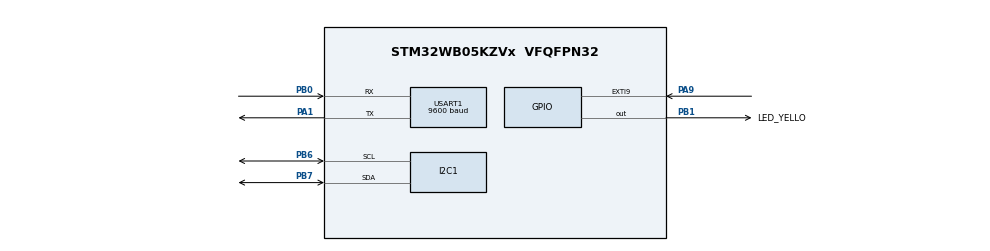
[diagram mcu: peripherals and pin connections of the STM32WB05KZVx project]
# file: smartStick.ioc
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I2C1.Timing=0x00303D5B
Mcu.Family=STM32WB0
Mcu.Name=STM32WB05KZVx
Mcu.Package=VFQFPN32
NVIC.GPIOA_IRQn=true\:1\:0\:false\:false\:true\:true\:true\:true
NVIC.I2C1_IRQn=true\:1\:0\:false\:false\:true\:true\:true\:true
NVIC.RADIO_RRM_IRQn=true\:0\:0\:false\:false\:true\:false\:true\:true
NVIC.RADIO_TIMER_CPU_WKUP_IRQn=true\:0\:0\:false\:false\:true\:false\:true\:true
NVIC.RADIO_TIMER_ERROR_IRQn=true\:0\:0\:false\:false\:true\:false\:true\:true
NVIC.RADIO_TXRX_IRQn=true\:0\:0\:false\:false\:true\:false\:true\:true
NVIC.RADIO_TXRX_SEQ_IRQn=true\:0\:0\:false\:false\:true\:false\:true\:true
NVIC.TIM16_IRQn=true\:1\:0\:false\:false\:true\:true\:true\:true
NVIC.USART1_IRQn=true\:1\:0\:false\:false\:true\:true\:true\:true
OSCIN.Mode=HSE-External-Oscillator
OSCIN.Signal=RCC_OSC_IN
OSCOUT.Mode=HSE-External-Oscillator
OSCOUT.Signal=RCC_OSC_OUT
PA1.Mode=Asynchronous
PA1.Signal=USART1_TX
PA9.GPIO_PuPd=GPIO_PULLDOWN
PA9.Signal=GPXTI9
PB0.Mode=Asynchronous
PB0.Signal=USART1_RX
PB1.GPIO_Label=LED_YELLO
PB1.Signal=GPIO_Output
PB12.Mode=LSE-External-Oscillator
PB12.Signal=RCC_OSC32_OUT
PB13.Mode=LSE-External-Oscillator
PB13.Signal=RCC_OSC32_IN
PB6.Mode=I2C
PB6.Signal=I2C1_SCL
PB7.Mode=I2C
PB7.Signal=I2C1_SDA
ProjectManager.HeapSize=0x000
ProjectManager.StackSize=0xC00
ProjectManager.TargetToolchain=STM32CubeIDE
RCC.BLEMultSource=RCC_RF_CLK_16M
RCC.HSE_VALUE=32000000
RCC.HSI_VALUE=64000000
RCC.RC64MPLLSource=RCC_LSCOSOURCE_PLL64
RCC.RTCClockSelection=RCC_RTC_WDG_BLEWKUP_CLKSOURCE_LSE
RF1.Mode=RF1_Activate
RF1.Signal=RADIO_RF1
STM32_BLE.AD_TYPE_COMPLETE_LOCAL_NAME=WMU_Heat30
STM32_BLE.AD_TYPE_COMPLETE_LOCAL_NAME_LENGTH=11
STM32_BLE.AD_TYPE_MANUFACTURER_DATA_NBR=12
STM32_BLE.BSP.number=1
STM32_BLE.CFG_GAP_DEVICE_NAME=WMU_Heat30
STM32_BLE.CFG_GAP_DEVICE_NAME_LENGTH=10
STM32_BLE.COMMON_BLE_STATUS-BLE_Server=Disabled
STM32_BLE.INCLUDE_AD_TYPE_COMPLETE_LOCAL_NAME=1
STM32_BLE.INCLUDE_AD_TYPE_MANUFACTURER_SPECIFIC_DATA=1
STM32_BLE.NUMBER_OF_SERVICES=1
STM32_BLE.SERVICE1_CHAR1_GATT_NOTIFY_READ_REQ_AND_WAIT_FOR_APPL_RESP=\ 
STM32_BLE.SERVICE1_CHAR1_GATT_NOTIFY_WRITE_REQ_AND_WAIT_FOR_APPL_RESP=\ 
STM32_BLE.SERVICE1_CHAR1_LENGTH_CHARACTERISTIC=CHAR_VALUE_LEN_VARIABLE
STM32_BLE.SERVICE1_CHAR1_LONG_NAME=My_PWM_Char
STM32_BLE.SERVICE1_CHAR1_PROP_READ=BLE_GATT_SRV_CHAR_PROP_READ
STM32_BLE.SERVICE1_CHAR1_PROP_WRITE_NO_RESP=BLE_GATT_SRV_CHAR_PROP_WRITE_NO_RESP
STM32_BLE.SERVICE1_CHAR1_SHORT_NAME=PWM_C
STM32_BLE.SERVICE1_CHAR1_UUID=19 ED 82 AE ED 21 4C 9D 41 45 22 8E 41 FE 00 00
STM32_BLE.SERVICE1_CHAR1_UUID_128_INPUT_TYPE=1
STM32_BLE.SERVICE1_CHAR1_VALUE_LENGTH=2
STM32_BLE.SERVICE1_CHAR2_GATT_NOTIFY_READ_REQ_AND_WAIT_FOR_APPL_RESP=\ 
STM32_BLE.SERVICE1_CHAR2_GATT_NOTIFY_WRITE_REQ_AND_WAIT_FOR_APPL_RESP=\ 
STM32_BLE.SERVICE1_CHAR2_LENGTH_CHARACTERISTIC=CHAR_VALUE_LEN_VARIABLE
STM32_BLE.SERVICE1_CHAR2_LONG_NAME=My_Temp_Char
STM32_BLE.SERVICE1_CHAR2_PROP_NOTIFY=BLE_GATT_SRV_CHAR_PROP_NOTIFY
STM32_BLE.SERVICE1_CHAR2_SHORT_NAME=TEMP_C
STM32_BLE.SERVICE1_CHAR2_UUID=A8 26 1B 36 07 EA F5 B7 88 46 E1 36 3E 48 B5 BE
STM32_BLE.SERVICE1_CHAR2_UUID_128_INPUT_TYPE=1
STM32_BLE.SERVICE1_CHAR2_VALUE_LENGTH=4
STM32_BLE.SERVICE1_LONG_NAME=P2P_Server
STM32_BLE.SERVICE1_NUMBER_OF_CHARACTERISTICS=2
STM32_BLE.SERVICE1_SHORT_NAME=P2P_Server
STM32_BLE.SERVICE1_UUID=4B 91 31 C3 C9 C5 CC 8F 9E 45 B5 1F 01 C2 AF 4F
STM32_BLE.SERVICE1_UUID_128_INPUT_TYPE=1
STM32_BLE0.BSP.STBoard=false
STM32_BLE0.BSP.api=Unknown
STM32_BLE0.BSP.instance=USART1
STM32_BLE0.BSP.ip=(LPU|US)ART
STM32_BLE0.BSP.mode=Asynchronous
STM32_BLE0.BSP.name=Serial Link for Traces
STM32_BLE0.BSP.solution=USART1
TIM16.Period=50000-1
TIM16.Prescaler=6400-1
USART1.BaudRate=9600
USART1.VirtualMode-Asynchronous=VM_ASYNC
VP_ADV_TRACE_VS_ADV_TRACE.Mode=ADV_TRACE_Enabled
VP_MEMORYMAP_VS_MEMORYMAP.Mode=CurAppReg
VP_MISC_VS_MISC.Mode=MISC_Enabled
VP_PKA_VS_PKA.Mode=PKA_Activate
VP_PWR_VS_SECSignals.Mode=Security/Privilege
VP_RADIO_TIMER_VS_RADIO.Mode=RADIO_Activate
VP_RNG_VS_RNG.Mode=RNG_Activate
VP_SEQUENCER_VS_SEQUENCER.Mode=SEQUENCER_Enabled
VP_STM32_BLE_VS_BLE_HOST_SP.Mode=BLE_Server
VP_TIM16_VS_ClockSourceINT.Mode=Enable_Timer
VP_TINY_LPM_VS_TINY_LPM.Mode=TINY_LPM_Enabled
board=custom

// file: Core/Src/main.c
/* USER CODE BEGIN Header */
/**
  ******************************************************************************
  * @file           : main.c
  * @brief          : Main program body
  ******************************************************************************
  * @attention
  *
  * Copyright (c) 2025 STMicroelectronics.
  * All rights reserved.
  *
  * This software is licensed under terms that can be found in the LICENSE file
  * in the root directory of this software component.
  * If no LICENSE file comes with this software, it is provided AS-IS.
  *
  ******************************************************************************
  */
/* USER CODE END Header */
#include "main.h"

/* USER CODE BEGIN Includes */
#include <stdio.h>
#include <string.h>

#include "air_app.h"
#include "bma456_app.h"
/* USER CODE END Includes */

I2C_HandleTypeDef hi2c1;

PKA_HandleTypeDef hpka;

RNG_HandleTypeDef hrng;

TIM_HandleTypeDef htim16;

UART_HandleTypeDef huart1;

void SystemClock_Config(void);
void PeriphCommonClock_Config(void);
static void MX_GPIO_Init(void);
static void MX_I2C1_Init(void);
static void MX_RNG_Init(void);
static void MX_RADIO_Init(void);
static void MX_RADIO_TIMER_Init(void);
static void MX_PKA_Init(void);
static void MX_TIM16_Init(void);
/* USER CODE BEGIN PFP */
void MX_USART1_UART_Init(void);
/* USER CODE END PFP */

int main(void)
{

  /* MCU Configuration--------------------------------------------------------*/

  /* Reset of all peripherals, Initializes the Flash interface and the Systick. */
  HAL_Init();

  /* Configure the system clock */
  SystemClock_Config();

  /* Configure the peripherals common clocks */
  PeriphCommonClock_Config();

  /* Initialize all configured peripherals */
  MX_GPIO_Init();
  MX_I2C1_Init();
  MX_RNG_Init();
  MX_RADIO_Init();
  MX_RADIO_TIMER_Init();
  MX_PKA_Init();
  MX_TIM16_Init();
  /* USER CODE BEGIN 2 */
  MX_USART1_UART_Init();

  if (air_app_init(&hi2c1, &huart1) != HAL_OK)
    {
      /* simple fault indication */
      HAL_Delay(200);
    }

  /* Initialize BMA456 accelerometer for impact detection */
  HAL_StatusTypeDef bma_status = bma456_app_init(&hi2c1, &huart1);
  if (bma_status != HAL_OK)
    {
      /* BMA456 initialization failed - continue anyway */
      HAL_Delay(100);
    }

  /* USER CODE END 2 */

  /* Init code for STM32_BLE */
  //MX_APPE_Init(NULL);

  /* Infinite loop */
  while (1)
  {
    //MX_APPE_Process();

    /* USER CODE BEGIN 3 */
	  air_app_process();
	      HAL_Delay(10); // small idle delay; BSEC scheduling still works
  }
  /* USER CODE END 3 */
}

void SystemClock_Config(void)
{
  RCC_OscInitTypeDef RCC_OscInitStruct = {0};
  RCC_ClkInitTypeDef RCC_ClkInitStruct = {0};

  /** Initializes the RCC Oscillators according to the specified parameters
  * in the RCC_OscInitTypeDef structure.
  */
  RCC_OscInitStruct.OscillatorType = RCC_OSCILLATORTYPE_HSE|RCC_OSCILLATORTYPE_LSE;
  RCC_OscInitStruct.HSEState = RCC_HSE_ON;
  RCC_OscInitStruct.LSEState = RCC_LSE_ON;
  if (HAL_RCC_OscConfig(&RCC_OscInitStruct) != HAL_OK)
  {
    Error_Handler();
  }

  /** Configure the SYSCLKSource and SYSCLKDivider
  */
  RCC_ClkInitStruct.SYSCLKSource = RCC_SYSCLKSOURCE_RC64MPLL;
  RCC_ClkInitStruct.SYSCLKDivider = RCC_RC64MPLL_DIV1;

  if (HAL_RCC_ClockConfig(&RCC_ClkInitStruct, FLASH_WAIT_STATES_1) != HAL_OK)
  {
    Error_Handler();
  }
}

void PeriphCommonClock_Config(void)
{
  RCC_PeriphCLKInitTypeDef PeriphClkInitStruct = {0};

  /** Initializes the peripherals clock
  */
  PeriphClkInitStruct.PeriphClockSelection = RCC_PERIPHCLK_SMPS;
  PeriphClkInitStruct.SmpsDivSelection = RCC_SMPSCLK_DIV4;

  if (HAL_RCCEx_PeriphCLKConfig(&PeriphClkInitStruct) != HAL_OK)
  {
    Error_Handler();
  }
}

static void MX_I2C1_Init(void)
{

  hi2c1.Instance = I2C1;
  hi2c1.Init.Timing = 0x00303D5B;
  hi2c1.Init.OwnAddress1 = 0;
  hi2c1.Init.AddressingMode = I2C_ADDRESSINGMODE_7BIT;
  hi2c1.Init.DualAddressMode = I2C_DUALADDRESS_DISABLE;
  hi2c1.Init.OwnAddress2 = 0;
  hi2c1.Init.OwnAddress2Masks = I2C_OA2_NOMASK;
  hi2c1.Init.GeneralCallMode = I2C_GENERALCALL_DISABLE;
  hi2c1.Init.NoStretchMode = I2C_NOSTRETCH_DISABLE;
  if (HAL_I2C_Init(&hi2c1) != HAL_OK)
  {
    Error_Handler();
  }

  /** Configure Analogue filter
  */
  if (HAL_I2CEx_ConfigAnalogFilter(&hi2c1, I2C_ANALOGFILTER_ENABLE) != HAL_OK)
  {
    Error_Handler();
  }

  /** Configure Digital filter
  */
  if (HAL_I2CEx_ConfigDigitalFilter(&hi2c1, 0) != HAL_OK)
  {
    Error_Handler();
  }

}

static void MX_PKA_Init(void)
{

  hpka.Instance = PKA;
  if (HAL_PKA_Init(&hpka) != HAL_OK)
  {
    Error_Handler();
  }

}

static void MX_RADIO_Init(void)
{

  RADIO_HandleTypeDef hradio = {0};

  if (__HAL_RCC_RADIO_IS_CLK_DISABLED())
  {
    /* Radio Peripheral reset */
    __HAL_RCC_RADIO_FORCE_RESET();
    __HAL_RCC_RADIO_RELEASE_RESET();

    /* Enable Radio peripheral clock */
    __HAL_RCC_RADIO_CLK_ENABLE();
  }
  hradio.Instance = RADIO;
  HAL_RADIO_Init(&hradio);

}

static void MX_RADIO_TIMER_Init(void)
{

  RADIO_TIMER_InitTypeDef RADIO_TIMER_InitStruct = {0};

  if (__HAL_RCC_RADIO_IS_CLK_DISABLED())
  {
    /* Radio Peripheral reset */
    __HAL_RCC_RADIO_FORCE_RESET();
    __HAL_RCC_RADIO_RELEASE_RESET();

    /* Enable Radio peripheral clock */
    __HAL_RCC_RADIO_CLK_ENABLE();
  }
  /* Wait to be sure that the Radio Timer is active */
  while(LL_RADIO_TIMER_GetAbsoluteTime(WAKEUP) < 0x10);
  RADIO_TIMER_InitStruct.XTAL_StartupTime = 320;
  RADIO_TIMER_InitStruct.enableInitialCalibration = FALSE;
  RADIO_TIMER_InitStruct.periodicCalibrationInterval = 0;
  HAL_RADIO_TIMER_Init(&RADIO_TIMER_InitStruct);

}

static void MX_RNG_Init(void)
{

  hrng.Instance = RNG;
  if (HAL_RNG_Init(&hrng) != HAL_OK)
  {
    Error_Handler();
  }

}

static void MX_TIM16_Init(void)
{

  htim16.Instance = TIM16;
  htim16.Init.Prescaler = 6400-1;
  htim16.Init.CounterMode = TIM_COUNTERMODE_UP;
  htim16.Init.Period = 50000-1;
  htim16.Init.ClockDivision = TIM_CLOCKDIVISION_DIV1;
  htim16.Init.RepetitionCounter = 0;
  htim16.Init.AutoReloadPreload = TIM_AUTORELOAD_PRELOAD_DISABLE;
  if (HAL_TIM_Base_Init(&htim16) != HAL_OK)
  {
    Error_Handler();
  }

}

void MX_USART1_UART_Init(void)
{

  huart1.Instance = USART1;
  huart1.Init.BaudRate = 9600;
  huart1.Init.WordLength = UART_WORDLENGTH_8B;
  huart1.Init.StopBits = UART_STOPBITS_1;
  huart1.Init.Parity = UART_PARITY_NONE;
  huart1.Init.Mode = UART_MODE_TX_RX;
  huart1.Init.HwFlowCtl = UART_HWCONTROL_NONE;
  huart1.Init.OverSampling = UART_OVERSAMPLING_16;
  huart1.Init.OneBitSampling = UART_ONE_BIT_SAMPLE_DISABLE;
  huart1.Init.ClockPrescaler = UART_PRESCALER_DIV1;
  huart1.AdvancedInit.AdvFeatureInit = UART_ADVFEATURE_NO_INIT;
  if (HAL_UART_Init(&huart1) != HAL_OK)
  {
    Error_Handler();
  }
  if (HAL_UARTEx_SetTxFifoThreshold(&huart1, UART_TXFIFO_THRESHOLD_1_8) != HAL_OK)
  {
    Error_Handler();
  }
  if (HAL_UARTEx_SetRxFifoThreshold(&huart1, UART_RXFIFO_THRESHOLD_1_8) != HAL_OK)
  {
    Error_Handler();
  }
  if (HAL_UARTEx_DisableFifoMode(&huart1) != HAL_OK)
  {
    Error_Handler();
  }

}

static void MX_GPIO_Init(void)
{
  GPIO_InitTypeDef GPIO_InitStruct = {0};

  /* GPIO Ports Clock Enable */
  __HAL_RCC_GPIOB_CLK_ENABLE();
  __HAL_RCC_GPIOA_CLK_ENABLE();

  /*Configure GPIO pin Output Level - LED is active LOW (RESET=ON, SET=OFF) */
  HAL_GPIO_WritePin(LED_YELLO_GPIO_Port, LED_YELLO_Pin, GPIO_PIN_SET);

  /*Configure GPIO pin : LED_YELLO_Pin */
  GPIO_InitStruct.Pin = LED_YELLO_Pin;
  GPIO_InitStruct.Mode = GPIO_MODE_OUTPUT_PP;
  GPIO_InitStruct.Pull = GPIO_NOPULL;
  GPIO_InitStruct.Speed = GPIO_SPEED_FREQ_LOW;
  HAL_GPIO_Init(LED_YELLO_GPIO_Port, &GPIO_InitStruct);

  /*Configure GPIO pin : PA9 */
  GPIO_InitStruct.Pin = GPIO_PIN_9;
  GPIO_InitStruct.Mode = GPIO_MODE_IT_RISING;
  GPIO_InitStruct.Pull = GPIO_PULLDOWN;
  HAL_GPIO_Init(GPIOA, &GPIO_InitStruct);

  /**/
  HAL_PWREx_DisableGPIOPullUp(PWR_GPIO_B, PWR_GPIO_BIT_1);

  /**/
  HAL_PWREx_DisableGPIOPullDown(PWR_GPIO_B, PWR_GPIO_BIT_1);

  /*RT DEBUG GPIO_Init */
  RT_DEBUG_GPIO_Init();

  /* EXTI interrupt init*/
  HAL_NVIC_SetPriority(GPIOA_IRQn, 1, 0);
  HAL_NVIC_EnableIRQ(GPIOA_IRQn);

}

void Error_Handler(void)
{
  __disable_irq();
  while (1)
  {
  }
}
